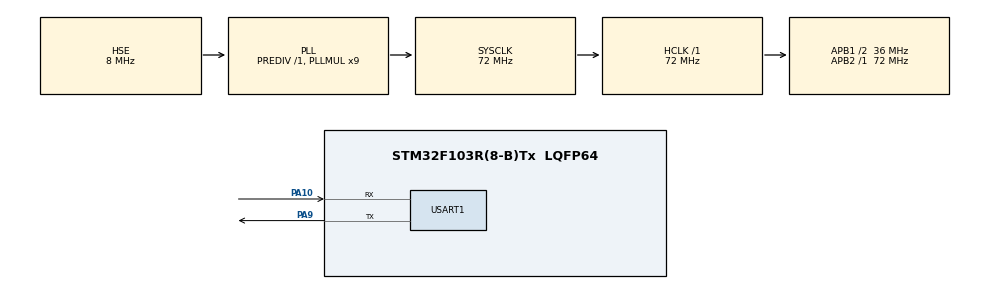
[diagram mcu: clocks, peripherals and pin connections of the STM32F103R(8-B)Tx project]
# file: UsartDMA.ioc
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Dma.Request0=USART1_RX
Dma.USART1_RX.0.Direction=DMA_PERIPH_TO_MEMORY
Dma.USART1_RX.0.Instance=DMA1_Channel5
Dma.USART1_RX.0.MemDataAlignment=DMA_MDATAALIGN_BYTE
Dma.USART1_RX.0.MemInc=DMA_MINC_ENABLE
Dma.USART1_RX.0.Mode=DMA_CIRCULAR
Dma.USART1_RX.0.PeriphDataAlignment=DMA_PDATAALIGN_BYTE
Dma.USART1_RX.0.PeriphInc=DMA_PINC_DISABLE
Dma.USART1_RX.0.Priority=DMA_PRIORITY_LOW
Mcu.Family=STM32F1
Mcu.Name=STM32F103R(8-B)Tx
Mcu.Package=LQFP64
NVIC.DMA1_Channel5_IRQn=true\:0\:0\:false\:false\:true\:false\:true
NVIC.PriorityGroup=NVIC_PRIORITYGROUP_4
NVIC.USART1_IRQn=true\:0\:0\:false\:false\:true\:true\:true
PA10.Mode=Asynchronous
PA10.Signal=USART1_RX
PA13.Mode=Trace_Asynchronous_SW
PA13.Signal=SYS_JTMS-SWDIO
PA14.Mode=Trace_Asynchronous_SW
PA14.Signal=SYS_JTCK-SWCLK
PA9.Mode=Asynchronous
PA9.Signal=USART1_TX
PB3.Mode=Trace_Asynchronous_SW
PB3.Signal=SYS_JTDO-TRACESWO
PD0-OSC_IN.Mode=HSE-External-Oscillator
PD0-OSC_IN.Signal=RCC_OSC_IN
PD1-OSC_OUT.Mode=HSE-External-Oscillator
PD1-OSC_OUT.Signal=RCC_OSC_OUT
ProjectManager.HeapSize=0x200
ProjectManager.StackSize=0x400
ProjectManager.TargetToolchain=STM32CubeIDE
RCC.AHBFreq_Value=72000000
RCC.APB1CLKDivider=RCC_HCLK_DIV2
RCC.APB1Freq_Value=36000000
RCC.APB1TimFreq_Value=72000000
RCC.APB2Freq_Value=72000000
RCC.APB2TimFreq_Value=72000000
RCC.HCLKFreq_Value=72000000
RCC.PLLMUL=RCC_PLL_MUL9
RCC.PLLSourceVirtual=RCC_PLLSOURCE_HSE
RCC.SYSCLKFreq_VALUE=72000000
RCC.SYSCLKSource=RCC_SYSCLKSOURCE_PLLCLK
RCC.USBFreq_Value=72000000
USART1.VirtualMode=VM_ASYNC
board=custom

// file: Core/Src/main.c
/* USER CODE BEGIN Header */
/**
 ******************************************************************************
 * @file           : main.c
 * @brief          : Main program body
 ******************************************************************************
 * @attention
 *
 * <h2><center>&copy; Copyright (c) 2019 STMicroelectronics.
 * All rights reserved.</center></h2>
 *
 * This software component is licensed by ST under BSD 3-Clause license,
 * the "License"; You may not use this file except in compliance with the
 * License. You may obtain a copy of the License at:
 *                        opensource.org/licenses/BSD-3-Clause
 *
 ******************************************************************************
 */
/* USER CODE END Header */

#include "main.h"

/* USER CODE BEGIN Includes */
#include <stdbool.h>
/* USER CODE END Includes */

UART_HandleTypeDef huart1;
DMA_HandleTypeDef hdma_usart1_rx;

/* USER CODE BEGIN PV */
#define DMA_RX_BUFFER_SIZE          64
uint8_t DMA_RX_Buffer[2][DMA_RX_BUFFER_SIZE];
bool Usart1CurrentBuffer=false;

#define UART_BUFFER_SIZE            256
uint8_t UART_Buffer[UART_BUFFER_SIZE];
size_t Write;
size_t len, tocopy;
uint8_t* ptr;
/* USER CODE END PV */

void SystemClock_Config(void);
static void MX_GPIO_Init(void);
static void MX_DMA_Init(void);
static void MX_USART1_UART_Init(void);
/* USER CODE BEGIN PFP */
int _write(int file, char *ptr, int len)
{
	/* Implement your write code here, this is used by puts and printf for example */

		int i=0;
	  for(i=0 ; i<len ; i++)
	    ITM_SendChar((*ptr++));
	  return len;

//	HAL_UART_Transmit(&huart1, ptr, len,5);
//	return  len;

}
void USART_IrqHandler (UART_HandleTypeDef *huart, DMA_HandleTypeDef *hdma)
{
	if (huart->Instance->SR & UART_FLAG_IDLE)           /* if Idle flag is set */
	{
		volatile uint32_t tmp;                  /* Must be volatile to prevent optimizations */

	__HAL_DMA_DISABLE (hdma);       /* Disabling DMA will force transfer complete interrupt if enabled */
		printf("idle int\n");
		DMA_IrqHandler (hdma, huart);
		__HAL_DMA_ENABLE(hdma);
		tmp = huart->Instance->SR;                       /* Read status register */
		tmp = huart->Instance->DR;                       /* Read data register */
	}
}

void DMA_IrqHandler (DMA_HandleTypeDef *hdma, UART_HandleTypeDef *huart)
{
//	//if(__HAL_DMA_GET_IT_SOURCE(hdma, DMA_IT_HT) != RESET) return;
//	typedef struct
//	{
//		__IO uint32_t ISR;   /*!< DMA interrupt status register */
//		__IO uint32_t Reserved0;
//		__IO uint32_t IFCR;  /*!< DMA interrupt flag clear register */
//	} DMA_Base_Registers;
//
//	DMA_Base_Registers *regs = (DMA_Base_Registers *)hdma->DmaBaseAddress;

	if(__HAL_DMA_GET_IT_SOURCE(hdma, DMA_IT_TC) != RESET)   // if the source is TC
	{
		/* Clear the transfer complete flag */
		/* Important! DMA stream won't start if all flags are not cleared first */
		__HAL_DMA_CLEAR_FLAG(hdma, __HAL_DMA_GET_TC_FLAG_INDEX(hdma));

		/* Get the length of the data */
		len =  64-hdma->Instance->CNDTR;
		printf("dma int len=%d\n",len);
		/* UNCOMMENT BELOW TO transmit the data via uart */

		HAL_UART_Transmit(&huart1, DMA_RX_Buffer[0], len, 10);
		hdma->Instance->CNDTR=64;
		//Usart1CurrentBuffer=!Usart1CurrentBuffer;
		//hdma->Instance->CMAR = (uint32_t)DMA_RX_Buffer[Usart1CurrentBuffer];
		/* Prepare DMA for next transfer no need in dma circular mode */

		//HAL_UART_Receive_DMA (&huart1, DMA_RX_Buffer, 64);
		// regs->IFCR = 0x3FU << hdma->ChannelIndex; // clear all interrupts
		//		hdma->Instance->CMAR = (uint32_t)DMA_RX_Buffer;   /* Set memory address for DMA again */
		//        hdma->Instance->CNDTR = DMA_RX_BUFFER_SIZE;    /* Set number of bytes to receive */
		//        hdma->Instance->CCR |= DMA_CCR_EN;            /* Start DMA transfer */
	}
}
/* USER CODE END PFP */

int main(void)
{

	/* MCU Configuration--------------------------------------------------------*/

	/* Reset of all peripherals, Initializes the Flash interface and the Systick. */
	HAL_Init();

	/* Configure the system clock */
	SystemClock_Config();

	/* Initialize all configured peripherals */
	MX_GPIO_Init();
	MX_DMA_Init();
	MX_USART1_UART_Init();
	/* USER CODE BEGIN 2 */

	__HAL_UART_ENABLE_IT(&huart1, UART_IT_IDLE);   // enable idle line interrupt

	//	hdma_usart1_rx.Instance->CCR &= ~DMA_SxCR_HTIE;
	HAL_UART_Receive_DMA (&huart1, DMA_RX_Buffer[0], 64);
	__HAL_DMA_ENABLE_IT(&hdma_usart1_rx,DMA_IT_TC);
	__HAL_DMA_DISABLE_IT(&hdma_usart1_rx, DMA_IT_HT); 	// discable half complete interrupt
	__HAL_DMA_DISABLE_IT(&hdma_usart1_rx, DMA_IT_TE); 	// discable error transfer interrupt
	/* USER CODE END 2 */

	/* Infinite loop */
	/* USER CODE BEGIN WHILE */
	printf("start program ....\n");
	while (1)
	{
		/* USER CODE END WHILE */

		/* USER CODE BEGIN 3 */
		//  printf("DMA CCR=%x\n",DMA1_Channel5->CCR);
		HAL_Delay(1000);

	}
	/* USER CODE END 3 */
}

void SystemClock_Config(void)
{
	RCC_OscInitTypeDef RCC_OscInitStruct = {0};
	RCC_ClkInitTypeDef RCC_ClkInitStruct = {0};

	/** Initializes the CPU, AHB and APB busses clocks
	 */
	RCC_OscInitStruct.OscillatorType = RCC_OSCILLATORTYPE_HSE;
	RCC_OscInitStruct.HSEState = RCC_HSE_ON;
	RCC_OscInitStruct.HSEPredivValue = RCC_HSE_PREDIV_DIV1;
	RCC_OscInitStruct.HSIState = RCC_HSI_ON;
	RCC_OscInitStruct.PLL.PLLState = RCC_PLL_ON;
	RCC_OscInitStruct.PLL.PLLSource = RCC_PLLSOURCE_HSE;
	RCC_OscInitStruct.PLL.PLLMUL = RCC_PLL_MUL9;
	if (HAL_RCC_OscConfig(&RCC_OscInitStruct) != HAL_OK)
	{
		Error_Handler();
	}
	/** Initializes the CPU, AHB and APB busses clocks
	 */
	RCC_ClkInitStruct.ClockType = RCC_CLOCKTYPE_HCLK|RCC_CLOCKTYPE_SYSCLK
			|RCC_CLOCKTYPE_PCLK1|RCC_CLOCKTYPE_PCLK2;
	RCC_ClkInitStruct.SYSCLKSource = RCC_SYSCLKSOURCE_PLLCLK;
	RCC_ClkInitStruct.AHBCLKDivider = RCC_SYSCLK_DIV1;
	RCC_ClkInitStruct.APB1CLKDivider = RCC_HCLK_DIV2;
	RCC_ClkInitStruct.APB2CLKDivider = RCC_HCLK_DIV1;

	if (HAL_RCC_ClockConfig(&RCC_ClkInitStruct, FLASH_LATENCY_2) != HAL_OK)
	{
		Error_Handler();
	}
}

static void MX_USART1_UART_Init(void)
{

	huart1.Instance = USART1;
	huart1.Init.BaudRate = 115200;
	huart1.Init.WordLength = UART_WORDLENGTH_8B;
	huart1.Init.StopBits = UART_STOPBITS_1;
	huart1.Init.Parity = UART_PARITY_NONE;
	huart1.Init.Mode = UART_MODE_TX_RX;
	huart1.Init.HwFlowCtl = UART_HWCONTROL_NONE;
	huart1.Init.OverSampling = UART_OVERSAMPLING_16;
	if (HAL_UART_Init(&huart1) != HAL_OK)
	{
		Error_Handler();
	}

}

static void MX_DMA_Init(void)
{

	/* DMA controller clock enable */
	__HAL_RCC_DMA1_CLK_ENABLE();

	/* DMA interrupt init */
	/* DMA1_Channel5_IRQn interrupt configuration */
	HAL_NVIC_SetPriority(DMA1_Channel5_IRQn, 0, 0);
	HAL_NVIC_EnableIRQ(DMA1_Channel5_IRQn);

}

static void MX_GPIO_Init(void)
{

	/* GPIO Ports Clock Enable */
	__HAL_RCC_GPIOD_CLK_ENABLE();
	__HAL_RCC_GPIOA_CLK_ENABLE();
	__HAL_RCC_GPIOB_CLK_ENABLE();

}

void Error_Handler(void)
{
}

/************************ (C) COPYRIGHT STMicroelectronics *****END OF FILE****/
